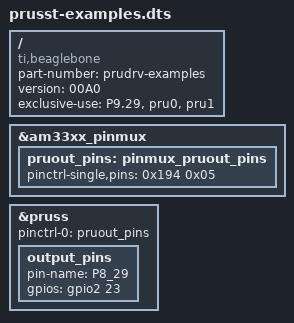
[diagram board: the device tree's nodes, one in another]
// Copyright (c) 2016 Serge Barral
// 
// Licensed under the Apache License, Version 2.0 or the MIT license, at your
// option.

/dts-v1/;
/plugin/;

/ {
    compatible = "ti,beaglebone", "ti,beaglebone-black", "ti,beaglebone-green";

    // identification
    part-number = "prudrv-examples";
    version = "00A0";

    // resources
    exclusive-use =
        "P9.29",
        "pru0",
        "pru1";


    // pinmux
    fragment@0 {
        target = <&am33xx_pinmux>;
        __overlay__ {
            pruout_pins: pinmux_pruout_pins {
                pinctrl-single,pins = <
                    0x194 0x05 // P9.29: MODE 5 (pr1_pru0_pru_r30_1), OUTPUT
                >;
            };
        };
    };


    // PRU
    fragment@1 {
        target = <&pruss>;
        __overlay__ {
            status        = "okay";
            pinctrl-names = "default";
            pinctrl-0     = <&pruout_pins>;

            output_pins {
                pin-name = "P8_29";
                gpios = <&gpio2 23 0>;
            };
        };
    };
};

